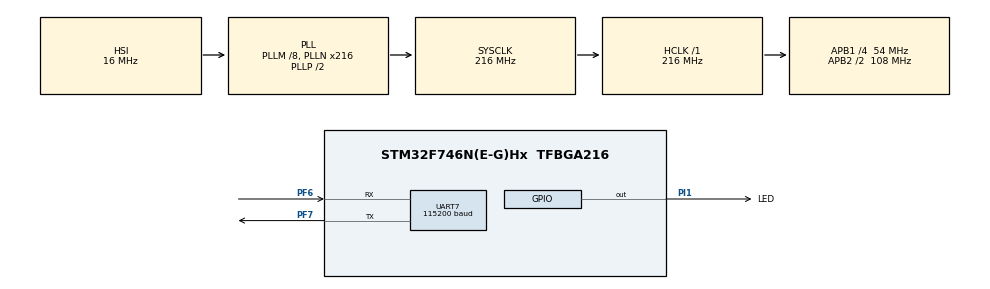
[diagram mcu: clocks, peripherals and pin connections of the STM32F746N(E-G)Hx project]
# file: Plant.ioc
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Mcu.Family=STM32F7
Mcu.Name=STM32F746N(E-G)Hx
Mcu.Package=TFBGA216
NVIC.PriorityGroup=NVIC_PRIORITYGROUP_4
NVIC.TIM1_UP_TIM10_IRQn=true\:0\:0\:false\:false\:true
NVIC.UART7_IRQn=true\:0\:0\:false\:false\:true
PF6.Mode=Asynchronous
PF6.Signal=UART7_RX
PF7.Mode=Asynchronous
PF7.Signal=UART7_TX
PI1.GPIO_Label=LED
PI1.Signal=GPIO_Output
ProjectManager.HeapSize=0x200
ProjectManager.StackSize=0x400
ProjectManager.TargetToolchain=SW4STM32
RCC.AHBFreq_Value=216000000
RCC.APB1CLKDivider=RCC_HCLK_DIV4
RCC.APB1Freq_Value=54000000
RCC.APB1TimFreq_Value=108000000
RCC.APB2CLKDivider=RCC_HCLK_DIV2
RCC.APB2Freq_Value=108000000
RCC.APB2TimFreq_Value=216000000
RCC.CortexFreq_Value=216000000
RCC.HCLKFreq_Value=216000000
RCC.HSE_VALUE=25000000
RCC.HSI_VALUE=16000000
RCC.LSE_VALUE=32768
RCC.PLLM=8
RCC.PLLN=216
RCC.SYSCLKFreq_VALUE=216000000
RCC.SYSCLKSource=RCC_SYSCLKSOURCE_PLLCLK
RCC.USBFreq_Value=216000000
RCC.VCOOutputFreq_Value=432000000
TIM10.Period=9999
TIM10.Prescaler=10799
UART7.BaudRate=115200
UART7.WordLength=UART_WORDLENGTH_8B
VP_TIM10_VS_ClockSourceINT.Mode=Enable_Timer
board=Plant

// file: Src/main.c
/**
  ******************************************************************************
  * File Name          : main.c
  * Description        : Main program body
  ******************************************************************************
  *
  * COPYRIGHT(c) 2016 STMicroelectronics
  *
  * Redistribution and use in source and binary forms, with or without modification,
  * are permitted provided that the following conditions are met:
  *   1. Redistributions of source code must retain the above copyright notice,
  *      this list of conditions and the following disclaimer.
  *   2. Redistributions in binary form must reproduce the above copyright notice,
  *      this list of conditions and the following disclaimer in the documentation
  *      and/or other materials provided with the distribution.
  *   3. Neither the name of STMicroelectronics nor the names of its contributors
  *      may be used to endorse or promote products derived from this software
  *      without specific prior written permission.
  *
  * THIS SOFTWARE IS PROVIDED BY THE COPYRIGHT HOLDERS AND CONTRIBUTORS "AS IS"
  * AND ANY EXPRESS OR IMPLIED WARRANTIES, INCLUDING, BUT NOT LIMITED TO, THE
  * IMPLIED WARRANTIES OF MERCHANTABILITY AND FITNESS FOR A PARTICULAR PURPOSE ARE
  * DISCLAIMED. IN NO EVENT SHALL THE COPYRIGHT HOLDER OR CONTRIBUTORS BE LIABLE
  * FOR ANY DIRECT, INDIRECT, INCIDENTAL, SPECIAL, EXEMPLARY, OR CONSEQUENTIAL
  * DAMAGES (INCLUDING, BUT NOT LIMITED TO, PROCUREMENT OF SUBSTITUTE GOODS OR
  * SERVICES; LOSS OF USE, DATA, OR PROFITS; OR BUSINESS INTERRUPTION) HOWEVER
  * CAUSED AND ON ANY THEORY OF LIABILITY, WHETHER IN CONTRACT, STRICT LIABILITY,
  * OR TORT (INCLUDING NEGLIGENCE OR OTHERWISE) ARISING IN ANY WAY OUT OF THE USE
  * OF THIS SOFTWARE, EVEN IF ADVISED OF THE POSSIBILITY OF SUCH DAMAGE.
  *
  ******************************************************************************
  */
#include "stm32f7xx_hal.h"

/* USER CODE BEGIN Includes */
#include "dc_model.h"
#include <stdlib.h>
#include <string.h>
/* USER CODE END Includes */

TIM_HandleTypeDef htim10;

UART_HandleTypeDef huart7;

/* USER CODE BEGIN PV */
/* Private variables ---------------------------------------------------------*/
typedef enum
{
	STOP,
	RUN
}motor_state;
dc_data d;
model_parameters par;
states x;
uint8_t recieve[10];
char send[20] = "x-12.234y-12.234";
char s1[9];
char s2[9];
char s_temp[10];
volatile float u=0.0;
motor_state M = STOP;
/* USER CODE END PV */

void SystemClock_Config(void);
void Error_Handler(void);
static void MX_GPIO_Init(void);
static void MX_TIM10_Init(void);
static void MX_UART7_Init(void);

/* USER CODE BEGIN PFP */
/* Private function prototypes -----------------------------------------------*/
void convertD2S(float x, float y, char* s2, char* res)
{
	int dz = (int)x;
	int temp = x*1000;
	int val = temp%1000;
	if(x<0)
	{
		int c_abs,d_abs;
		c_abs = abs(dz);
		d_abs = abs(val);
		if(d_abs<10)
			sprintf(res,"x-%d.00%d",c_abs,d_abs);
		else if((d_abs<100)&&(d_abs>9))
			sprintf(res,"x-%d.0%d",c_abs,d_abs);
		else
			sprintf(res,"x-%d.%d",c_abs,d_abs);
	}
	else
	{
		int d_abs;
		d_abs = abs(val);
		if(d_abs<10)
			sprintf(res,"x%d.00%d",dz,d_abs);
		else if((d_abs<100)&&(d_abs>9))
			sprintf(res,"x%d.0%d",dz,d_abs);
		else
			sprintf(res,"x%d.%d",dz,d_abs);
	}
	int dz2 = (int)y;
	int temp2 = y*1000;
	int val2 = temp2%1000;
	if(y<0)
	{
		int c_abs,d_abs;
		c_abs = abs(dz2);
		d_abs = abs(val2);
		if(d_abs<10)
			sprintf(s2,"y-%d.00%d",c_abs,d_abs);
		else if((d_abs<100)&&(d_abs>9))
			sprintf(s2,"y-%d.0%d",c_abs,d_abs);
		else
			sprintf(s2,"y-%d.%d",c_abs,d_abs);
	}
	else
	{
		int d_abs;
		d_abs = abs(val2);
		if(d_abs<10)
			sprintf(s2,"y%d.00%d",dz2,d_abs);
		else if((d_abs<100)&&(d_abs>9))
			sprintf(s2,"y%d.0%d",dz2,d_abs);
		else
			sprintf(s2,"y%d.%d",dz2,d_abs);
	}
	strncat(res,s2,20);
}

void HAL_TIM_PeriodElapsedCallback(TIM_HandleTypeDef *htim)
{
	if(htim->Instance == TIM10)
	{
		if(M == RUN)
		{
			rk4(&x,&par,u,0.01f);
			//x1
/*
			int dz = (int)x.x1;
			int val = x.x1*1000;
			val = val%1000;
			int dz2 = (int)x.x2;
			int val2 = x.x2*1000;
			val2 = val2%1000;
			if((val<0) && (dz>=0))
			{
				if((val2<0) && (dz2>=0))
					sprintf(send,"x-%d.%dy-%d.%d",dz,(-1*val),dz2,(-1*val2));
				else if((val2<0)&&(dz2<0))
					sprintf(send,"x-%d.%dy%d.%d",dz,(-1*val),dz2,(-1*val2));
				else
					sprintf(send,"x-%d.%dy%d.%d",dz,(-1*val),dz2,val2);
			}
			else if((val<0)&&(dz<0))
			{
				if((val2<0) && (dz2>=0))
					sprintf(send,"x%d.%dy-%d.%d",dz,(-1*val),dz2,(-1*val2));
				else if((val2<0)&&(dz2<0))
					sprintf(send,"x%d.%dy%d.%d",dz,(-1*val),dz2,(-1*val2));
				else
					sprintf(send,"x%d.%dy%d.%d",dz,(-1*val),dz2,val2);
			}
			else
			{
				if((val2<0) && (dz2>=0))
					sprintf(send,"x%d.%dy-%d.%d",dz,val,dz2,(-1*val2));
				else if((val<0)&&(dz2<0))
					sprintf(send,"x%d.%dy%d.%d",dz,val,dz2,(-1*val2));
				else
					sprintf(send,"x%d.%dy%d.%d",dz,val,dz2,val2);

			}*/
			convertD2S(x.x1,x.x2,s_temp,send);
			HAL_UART_Transmit_IT(&huart7,(uint8_t*)send,20);
			HAL_UART_Receive_IT(&huart7,recieve,20);
		}
	}
}

void HAL_UART_RxCpltCallback(UART_HandleTypeDef *huart)
{
	int i=1;
	char temp[9];
	switch(recieve[0])
	{
		case 'r':
			M = RUN;
			HAL_GPIO_WritePin(LED_GPIO_Port,LED_Pin,SET);
			HAL_TIM_Base_Start_IT(&htim10);
			break;
		case 's':
			M = STOP;
			u = 0.0;
			HAL_GPIO_WritePin(LED_GPIO_Port,LED_Pin,RESET);
			HAL_TIM_Base_Stop_IT(&htim10);
			break;
		case 'u':
			while(recieve[i]!='\0'&& (i<20))
			{
				temp[i-1]= recieve[i];
				i++;
			}
			u = atof(temp);
			break;
        case 'w':
            break;

	}
	HAL_UART_Receive_IT(&huart7,recieve,20);

}

/* USER CODE END PFP */

int main(void)
{

  /* USER CODE BEGIN 1 */
	d.R = 2;
	d.ke = 0.1;
	d.km = 0.1;
	d.J = 0.1;
	d.Mobc = 0.98;
	set_parameters(&d,&par);
	x.x1 = 0;
	x.x2 = 0;

  /* USER CODE END 1 */

  /* MCU Configuration----------------------------------------------------------*/

  /* Reset of all peripherals, Initializes the Flash interface and the Systick. */
  HAL_Init();

  /* Configure the system clock */
  SystemClock_Config();

  /* Initialize all configured peripherals */
  MX_GPIO_Init();
  MX_TIM10_Init();
  MX_UART7_Init();

  /* USER CODE BEGIN 2 */

  HAL_UART_Receive_IT(&huart7,recieve,20);
  /* USER CODE END 2 */

  /* Infinite loop */
  while (1)
  {

  }

}

/** System Clock Configuration
*/
void SystemClock_Config(void)
{

  RCC_OscInitTypeDef RCC_OscInitStruct;
  RCC_ClkInitTypeDef RCC_ClkInitStruct;
  RCC_PeriphCLKInitTypeDef PeriphClkInitStruct;

  __HAL_RCC_PWR_CLK_ENABLE();

  __HAL_PWR_VOLTAGESCALING_CONFIG(PWR_REGULATOR_VOLTAGE_SCALE1);

  RCC_OscInitStruct.OscillatorType = RCC_OSCILLATORTYPE_HSI;
  RCC_OscInitStruct.HSIState = RCC_HSI_ON;
  RCC_OscInitStruct.HSICalibrationValue = 16;
  RCC_OscInitStruct.PLL.PLLState = RCC_PLL_ON;
  RCC_OscInitStruct.PLL.PLLSource = RCC_PLLSOURCE_HSI;
  RCC_OscInitStruct.PLL.PLLM = 8;
  RCC_OscInitStruct.PLL.PLLN = 216;
  RCC_OscInitStruct.PLL.PLLP = RCC_PLLP_DIV2;
  RCC_OscInitStruct.PLL.PLLQ = 2;
  if (HAL_RCC_OscConfig(&RCC_OscInitStruct) != HAL_OK)
  {
    Error_Handler();
  }

  if (HAL_PWREx_EnableOverDrive() != HAL_OK)
  {
    Error_Handler();
  }

  RCC_ClkInitStruct.ClockType = RCC_CLOCKTYPE_HCLK|RCC_CLOCKTYPE_SYSCLK
                              |RCC_CLOCKTYPE_PCLK1|RCC_CLOCKTYPE_PCLK2;
  RCC_ClkInitStruct.SYSCLKSource = RCC_SYSCLKSOURCE_PLLCLK;
  RCC_ClkInitStruct.AHBCLKDivider = RCC_SYSCLK_DIV1;
  RCC_ClkInitStruct.APB1CLKDivider = RCC_HCLK_DIV4;
  RCC_ClkInitStruct.APB2CLKDivider = RCC_HCLK_DIV2;
  if (HAL_RCC_ClockConfig(&RCC_ClkInitStruct, FLASH_LATENCY_7) != HAL_OK)
  {
    Error_Handler();
  }

  PeriphClkInitStruct.PeriphClockSelection = RCC_PERIPHCLK_UART7;
  PeriphClkInitStruct.Uart7ClockSelection = RCC_UART7CLKSOURCE_PCLK1;
  if (HAL_RCCEx_PeriphCLKConfig(&PeriphClkInitStruct) != HAL_OK)
  {
    Error_Handler();
  }

  HAL_SYSTICK_Config(HAL_RCC_GetHCLKFreq()/1000);

  HAL_SYSTICK_CLKSourceConfig(SYSTICK_CLKSOURCE_HCLK);

  /* SysTick_IRQn interrupt configuration */
  HAL_NVIC_SetPriority(SysTick_IRQn, 0, 0);
}

/* TIM10 init function */
static void MX_TIM10_Init(void)
{

  htim10.Instance = TIM10;
  htim10.Init.Prescaler = 21599;
  htim10.Init.CounterMode = TIM_COUNTERMODE_UP;
  htim10.Init.Period = 99;
  htim10.Init.ClockDivision = TIM_CLOCKDIVISION_DIV1;
  if (HAL_TIM_Base_Init(&htim10) != HAL_OK)
  {
    Error_Handler();
  }

}

/* UART7 init function */
static void MX_UART7_Init(void)
{

  huart7.Instance = UART7;
  huart7.Init.BaudRate = 115200;
  huart7.Init.WordLength = UART_WORDLENGTH_8B;
  huart7.Init.StopBits = UART_STOPBITS_1;
  huart7.Init.Parity = UART_PARITY_NONE;
  huart7.Init.Mode = UART_MODE_TX_RX;
  huart7.Init.HwFlowCtl = UART_HWCONTROL_NONE;
  huart7.Init.OverSampling = UART_OVERSAMPLING_16;
  huart7.Init.OneBitSampling = UART_ONE_BIT_SAMPLE_DISABLE;
  huart7.AdvancedInit.AdvFeatureInit = UART_ADVFEATURE_NO_INIT;
  if (HAL_UART_Init(&huart7) != HAL_OK)
  {
    Error_Handler();
  }

}

/** Configure pins as
        * Analog
        * Input
        * Output
        * EVENT_OUT
        * EXTI
*/
static void MX_GPIO_Init(void)
{

  GPIO_InitTypeDef GPIO_InitStruct;

  /* GPIO Ports Clock Enable */
  __HAL_RCC_GPIOI_CLK_ENABLE();
  __HAL_RCC_GPIOF_CLK_ENABLE();

  /*Configure GPIO pin Output Level */
  HAL_GPIO_WritePin(LED_GPIO_Port, LED_Pin, GPIO_PIN_RESET);

  /*Configure GPIO pin : LED_Pin */
  GPIO_InitStruct.Pin = LED_Pin;
  GPIO_InitStruct.Mode = GPIO_MODE_OUTPUT_PP;
  GPIO_InitStruct.Pull = GPIO_NOPULL;
  GPIO_InitStruct.Speed = GPIO_SPEED_FREQ_LOW;
  HAL_GPIO_Init(LED_GPIO_Port, &GPIO_InitStruct);

}

void Error_Handler(void)
{
  while(1)
  {
  }
}

/************************ (C) COPYRIGHT STMicroelectronics *****END OF FILE****/
